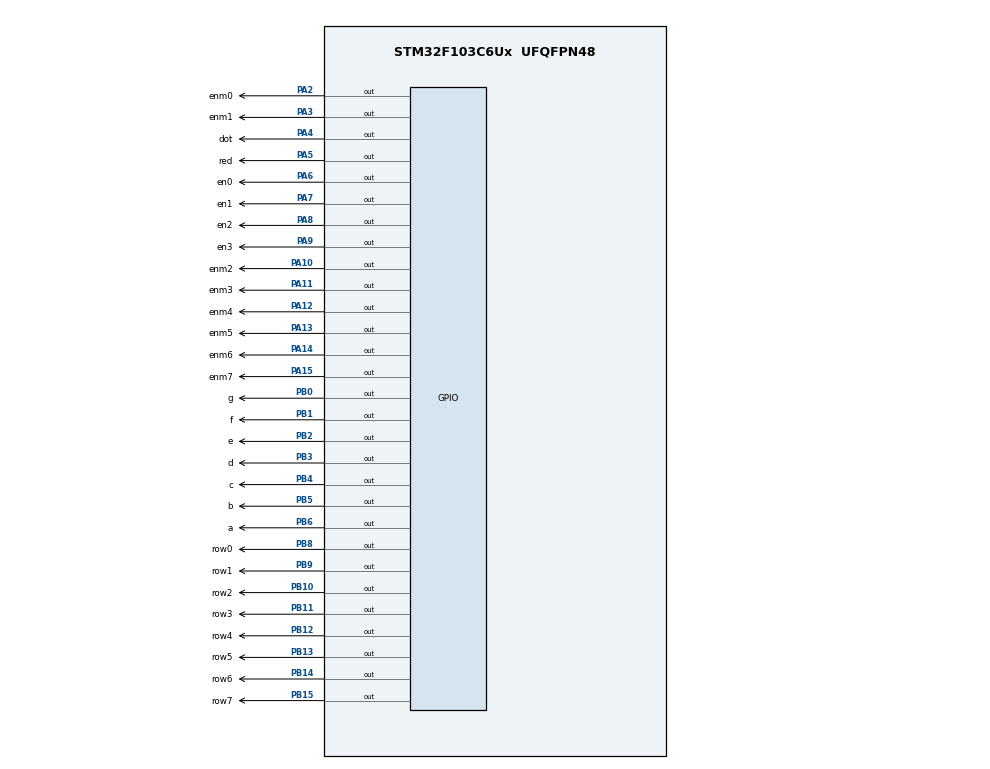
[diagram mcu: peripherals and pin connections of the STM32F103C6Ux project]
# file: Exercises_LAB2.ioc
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Mcu.Family=STM32F1
Mcu.Name=STM32F103C6Ux
Mcu.Package=UFQFPN48
NVIC.PriorityGroup=NVIC_PRIORITYGROUP_4
NVIC.TIM2_IRQn=true\:0\:0\:false\:false\:true\:true\:true
PA10.GPIO_Label=enm2
PA10.Signal=GPIO_Output
PA11.GPIO_Label=enm3
PA11.Signal=GPIO_Output
PA12.GPIO_Label=enm4
PA12.Signal=GPIO_Output
PA13.GPIO_Label=enm5
PA13.Signal=GPIO_Output
PA14.GPIO_Label=enm6
PA14.Signal=GPIO_Output
PA15.GPIO_Label=enm7
PA15.Signal=GPIO_Output
PA2.GPIO_Label=enm0
PA2.Signal=GPIO_Output
PA3.GPIO_Label=enm1
PA3.Signal=GPIO_Output
PA4.GPIO_Label=dot
PA4.Signal=GPIO_Output
PA5.GPIO_Label=red
PA5.Signal=GPIO_Output
PA6.GPIO_Label=en0
PA6.Signal=GPIO_Output
PA7.GPIO_Label=en1
PA7.Signal=GPIO_Output
PA8.GPIO_Label=en2
PA8.Signal=GPIO_Output
PA9.GPIO_Label=en3
PA9.Signal=GPIO_Output
PB0.GPIO_Label=g
PB0.Signal=GPIO_Output
PB1.GPIO_Label=f
PB1.Signal=GPIO_Output
PB10.GPIO_Label=row2
PB10.Signal=GPIO_Output
PB11.GPIO_Label=row3
PB11.Signal=GPIO_Output
PB12.GPIO_Label=row4
PB12.Signal=GPIO_Output
PB13.GPIO_Label=row5
PB13.Signal=GPIO_Output
PB14.GPIO_Label=row6
PB14.Signal=GPIO_Output
PB15.GPIO_Label=row7
PB15.Signal=GPIO_Output
PB2.GPIO_Label=e
PB2.Signal=GPIO_Output
PB3.GPIO_Label=d
PB3.Signal=GPIO_Output
PB4.GPIO_Label=c
PB4.Signal=GPIO_Output
PB5.GPIO_Label=b
PB5.Signal=GPIO_Output
PB6.GPIO_Label=a
PB6.Signal=GPIO_Output
PB8.GPIO_Label=row0
PB8.Signal=GPIO_Output
PB9.GPIO_Label=row1
PB9.Signal=GPIO_Output
ProjectManager.HeapSize=0x200
ProjectManager.StackSize=0x400
ProjectManager.TargetToolchain=STM32CubeIDE
RCC.APB1Freq_Value=8000000
RCC.APB2Freq_Value=8000000
TIM2.Period=9
TIM2.Prescaler=7999
VP_SYS_VS_ND.Mode=No_Debug
VP_TIM2_VS_ClockSourceINT.Mode=Internal
board=custom

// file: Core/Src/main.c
/* USER CODE BEGIN Header */
/**
  ******************************************************************************
  * @file           : main.c
  * @brief          : Main program body
  ******************************************************************************
  * @attention
  *
  * <h2><center>&copy; Copyright (c) 2023 STMicroelectronics.
  * All rights reserved.</center></h2>
  *
  * This software component is licensed by ST under BSD 3-Clause license,
  * the "License"; You may not use this file except in compliance with the
  * License. You may obtain a copy of the License at:
  *                        opensource.org/licenses/BSD-3-Clause
  *
  ******************************************************************************
  */
/* USER CODE END Header */
#include "main.h"

//#include "software_timer.c"
#include "software_timer.h"//ADD

TIM_HandleTypeDef htim2;

void SystemClock_Config(void);
static void MX_GPIO_Init(void);
static void MX_TIM2_Init(void);

int timer1_counter = 0;
int timer2_counter = 0;
int timer3_counter = 0;
int timer4_counter = 0;
int timer1_flag = 0;
int timer2_flag = 0;
int timer3_flag = 0;
int timer4_flag = 0;

void setTimer1(int duration)
{
	timer1_counter = duration;
	timer1_flag = 0;
}

void setTimer2(int duration)
{
	timer2_counter = duration;
	timer2_flag = 0;
}

void setTimer3(int duration)
{
	timer3_counter = duration;
	timer3_flag = 0;
}

void setTimer4(int duration)
{
	timer4_counter = duration;
	timer4_flag = 0;
}

void timerRun()
{
	if(timer1_counter > 0)
	{
		timer1_counter--;
		if(timer1_counter <= 0)
		{
			timer1_flag = 1;
		}
	}
}

void timerRun2()
{
	if(timer2_counter > 0)
	{
		timer2_counter--;
		if(timer2_counter <= 0)
		{
			timer2_flag = 1;
		}
	}
}

void timerRun3()
{
	if(timer3_counter > 0)
	{
		timer3_counter--;
		if(timer3_counter <= 0)
		{
			timer3_flag = 1;
		}
	}
}

void timerRun4()
{
	if(timer4_counter > 0)
	{
		timer4_counter--;
		if(timer4_counter <= 0)
		{
			timer4_flag = 1;
		}
	}
}
//ADD

GPIO_TypeDef* seg_port[] = {a_GPIO_Port, b_GPIO_Port, c_GPIO_Port, d_GPIO_Port, e_GPIO_Port, f_GPIO_Port, g_GPIO_Port};
int seg_pin[] = {a_Pin, b_Pin, c_Pin, d_Pin, e_Pin, f_Pin, g_Pin};
int seg_config[10] = {0x01, 0x4F, 0x12, 0x06, 0x4C, 0x24, 0x20, 0x0F, 0x00, 0x04};
// Hexadecimal to Binary: 0x01->0x00000001, 0x4F->01001111, ...

void display7SEG(int num)
{
	GPIOB->ODR = seg_config[num];
}

const int MAX_LED = 4;
int index_led = 0;
int led_buffer[4] = {1, 2, 3, 4};
void update7SEG(int index)
{
    switch (index)
    {
        case 0:
            //Display the first 7SEG with led_buffer[0]
    		HAL_GPIO_WritePin(en0_GPIO_Port, en0_Pin, RESET);
    		HAL_GPIO_WritePin(GPIOA, en1_Pin | en2_Pin | en3_Pin, SET);
    		display7SEG(led_buffer[index]);
            break;
        case 1:
            //Display the second 7SEG with led_buffer[1]
  		    HAL_GPIO_WritePin(en1_GPIO_Port, en1_Pin, RESET);
    		HAL_GPIO_WritePin(GPIOA, en0_Pin | en2_Pin | en3_Pin, SET);
    		display7SEG(led_buffer[index]);
            break;
        case 2:
            //Display the third 7SEG with led_buffer[2]
  		    HAL_GPIO_WritePin(en2_GPIO_Port, en2_Pin, RESET);
    		HAL_GPIO_WritePin(GPIOA, en0_Pin | en1_Pin | en3_Pin, SET);
    		display7SEG(led_buffer[index]);
            break;
        case 3:
            //Display the forth 7SEG with led_buffer[3]
  		    HAL_GPIO_WritePin(en3_GPIO_Port, en3_Pin, RESET);
    		HAL_GPIO_WritePin(GPIOA, en0_Pin | en1_Pin | en2_Pin, SET);
    		display7SEG(led_buffer[index]);
            break;
        default:
            break;
    }
}

void updateClockBuffer(int hour, int minute)
{
    led_buffer[0] = hour / 10;
    led_buffer[1] = hour % 10;
    led_buffer[2] = minute / 10;
    led_buffer[3] = minute % 10;
}

const int MAX_LED_MATRIX = 8;
int index_led_matrix = 0;
int state = 0;
uint8_t matrix_buffer[8] = {0x01, 0x02, 0x03, 0x04, 0x05, 0x06, 0x07, 0x08};

uint8_t row_buffer[8] = {0x01, 0x02, 0x04, 0x08, 0x10, 0x20, 0x40, 0x80};

uint8_t col_buffer[8][8] =
{
{0x18, 0x3C, 0x66, 0x66, 0x7E, 0x7E, 0x66, 0x66},
{0x30, 0x78, 0xCC, 0xCC, 0xFC, 0xFC, 0xCC, 0xCC},
{0x60, 0xF0, 0x99, 0x99, 0xF9, 0xF9, 0x99, 0x99},
{0xC0, 0xE1, 0x33, 0x33, 0xF3, 0xF3, 0x33, 0x33},
{0x81, 0xC3, 0x66, 0x66, 0xE7, 0xE7, 0x66, 0x66},
{0x03, 0x87, 0xCC, 0xCC, 0xCF, 0xCF, 0xCC, 0xCC},
{0x06, 0x0F, 0x99, 0x99, 0x9F, 0x9F, 0x99, 0x99},
{0x0C, 0x1E, 0x33, 0x33, 0x3F, 0x3F, 0x33, 0x33}
};

void displayCol (int state, int index)
{
	  HAL_GPIO_WritePin(row0_GPIO_Port,row0_Pin, ((col_buffer[state][index]>>0)&0x01));
	  HAL_GPIO_WritePin(row1_GPIO_Port,row1_Pin, ((col_buffer[state][index]>>1)&0x01));
	  HAL_GPIO_WritePin(row2_GPIO_Port,row2_Pin, ((col_buffer[state][index]>>2)&0x01));
	  HAL_GPIO_WritePin(row3_GPIO_Port,row3_Pin, ((col_buffer[state][index]>>3)&0x01));
	  HAL_GPIO_WritePin(row4_GPIO_Port,row4_Pin, ((col_buffer[state][index]>>4)&0x01));
	  HAL_GPIO_WritePin(row5_GPIO_Port,row5_Pin, ((col_buffer[state][index]>>5)&0x01));
	  HAL_GPIO_WritePin(row6_GPIO_Port,row6_Pin, ((col_buffer[state][index]>>6)&0x01));
	  HAL_GPIO_WritePin(row7_GPIO_Port,row7_Pin, ((col_buffer[state][index]>>7)&0x01));
}

void displayRow (int index)
{
	  HAL_GPIO_WritePin(enm0_GPIO_Port, enm0_Pin, ((row_buffer[index]>>0)&0x01));
	  HAL_GPIO_WritePin(enm1_GPIO_Port, enm1_Pin, ((row_buffer[index]>>1)&0x01));
	  HAL_GPIO_WritePin(enm2_GPIO_Port, enm2_Pin, ((row_buffer[index]>>2)&0x01));
	  HAL_GPIO_WritePin(enm3_GPIO_Port, enm3_Pin, ((row_buffer[index]>>3)&0x01));
	  HAL_GPIO_WritePin(enm4_GPIO_Port, enm4_Pin, ((row_buffer[index]>>4)&0x01));
	  HAL_GPIO_WritePin(enm5_GPIO_Port, enm5_Pin, ((row_buffer[index]>>5)&0x01));
	  HAL_GPIO_WritePin(enm6_GPIO_Port, enm6_Pin, ((row_buffer[index]>>6)&0x01));
	  HAL_GPIO_WritePin(enm7_GPIO_Port, enm7_Pin, ((row_buffer[index]>>7)&0x01));
}

void updateLEDMatrix(int sate, int index)
{
    switch (index)
    {
        case 0:
        	displayRow(index);
        	displayCol(state, index);
            break;
        case 1:
        	displayRow(index);
        	displayCol(state, index);
            break;
        case 2:
        	displayRow(index);
        	displayCol(state, index);
            break;
        case 3:
        	displayRow(index);
        	displayCol(state, index);
            break;
        case 4:
        	displayRow(index);
        	displayCol(state, index);
            break;
        case 5:
        	displayRow(index);
        	displayCol(state, index);
            break;
        case 6:
        	displayRow(index);
        	displayCol(state, index);
            break;
        case 7:
        	displayRow(index);
        	displayCol(state, index);
            break;
        default:
            break;
    }
}

int main(void)
{

  /* MCU Configuration--------------------------------------------------------*/

  /* Reset of all peripherals, Initializes the Flash interface and the Systick. */
  HAL_Init();

  /* Configure the system clock */
  SystemClock_Config();

  /* Initialize all configured peripherals */
  MX_GPIO_Init();
  MX_TIM2_Init();
  /* USER CODE BEGIN 2 */
  HAL_TIM_Base_Start_IT(&htim2);
  /* USER CODE END 2 */

  /* Infinite loop */
  /* USER CODE BEGIN WHILE */
  int hour = 15, minute = 8, second = 50;
  setTimer1(25);
  setTimer2(100);
  setTimer3(3);
  setTimer4(100);
  while (1)
  {
    /* USER CODE END WHILE */

	  if(timer1_flag == 1)
	  {
		  setTimer1(25);
		  update7SEG(index_led++);
		  if(index_led >= 4)	index_led = 0;
	  }

	  if(timer2_flag == 1)
	  {
		    setTimer2(100);
		    second++;
		    if (second >= 60)
		    {
		        second = 0;
		        minute++;
		    }
		    if(minute >= 60)
		    {
		        minute = 0;
		        hour++;
		    }
		    if(hour >=24)
		    {
		        hour = 0;
		    }
		    updateClockBuffer(hour, minute);
	  }

	  if(timer3_flag == 1)
	  {
		  setTimer3(3);
		  updateLEDMatrix(state, index_led_matrix++);
	  }
	  if(timer4_flag == 1)
	  {
		  setTimer4(100);
		  HAL_GPIO_TogglePin(dot_GPIO_Port, dot_Pin);
	  }
	  if(index_led_matrix >= MAX_LED_MATRIX)
	  {
		  index_led_matrix = 0;
		  state++;
		  if(state >= MAX_LED_MATRIX)	state = 0;
	  }
  }
}

void SystemClock_Config(void)
{
  RCC_OscInitTypeDef RCC_OscInitStruct = {0};
  RCC_ClkInitTypeDef RCC_ClkInitStruct = {0};

  /** Initializes the RCC Oscillators according to the specified parameters
  * in the RCC_OscInitTypeDef structure.
  */
  RCC_OscInitStruct.OscillatorType = RCC_OSCILLATORTYPE_HSI;
  RCC_OscInitStruct.HSIState = RCC_HSI_ON;
  RCC_OscInitStruct.HSICalibrationValue = RCC_HSICALIBRATION_DEFAULT;
  RCC_OscInitStruct.PLL.PLLState = RCC_PLL_NONE;
  if (HAL_RCC_OscConfig(&RCC_OscInitStruct) != HAL_OK)
  {
    Error_Handler();
  }
  /** Initializes the CPU, AHB and APB buses clocks
  */
  RCC_ClkInitStruct.ClockType = RCC_CLOCKTYPE_HCLK|RCC_CLOCKTYPE_SYSCLK
                              |RCC_CLOCKTYPE_PCLK1|RCC_CLOCKTYPE_PCLK2;
  RCC_ClkInitStruct.SYSCLKSource = RCC_SYSCLKSOURCE_HSI;
  RCC_ClkInitStruct.AHBCLKDivider = RCC_SYSCLK_DIV1;
  RCC_ClkInitStruct.APB1CLKDivider = RCC_HCLK_DIV1;
  RCC_ClkInitStruct.APB2CLKDivider = RCC_HCLK_DIV1;

  if (HAL_RCC_ClockConfig(&RCC_ClkInitStruct, FLASH_LATENCY_0) != HAL_OK)
  {
    Error_Handler();
  }
}

static void MX_TIM2_Init(void)
{

  TIM_ClockConfigTypeDef sClockSourceConfig = {0};
  TIM_MasterConfigTypeDef sMasterConfig = {0};

  htim2.Instance = TIM2;
  htim2.Init.Prescaler = 7999;
  htim2.Init.CounterMode = TIM_COUNTERMODE_UP;
  htim2.Init.Period = 9;
  htim2.Init.ClockDivision = TIM_CLOCKDIVISION_DIV1;
  htim2.Init.AutoReloadPreload = TIM_AUTORELOAD_PRELOAD_DISABLE;
  if (HAL_TIM_Base_Init(&htim2) != HAL_OK)
  {
    Error_Handler();
  }
  sClockSourceConfig.ClockSource = TIM_CLOCKSOURCE_INTERNAL;
  if (HAL_TIM_ConfigClockSource(&htim2, &sClockSourceConfig) != HAL_OK)
  {
    Error_Handler();
  }
  sMasterConfig.MasterOutputTrigger = TIM_TRGO_RESET;
  sMasterConfig.MasterSlaveMode = TIM_MASTERSLAVEMODE_DISABLE;
  if (HAL_TIMEx_MasterConfigSynchronization(&htim2, &sMasterConfig) != HAL_OK)
  {
    Error_Handler();
  }

}

static void MX_GPIO_Init(void)
{
  GPIO_InitTypeDef GPIO_InitStruct = {0};

  /* GPIO Ports Clock Enable */
  __HAL_RCC_GPIOA_CLK_ENABLE();
  __HAL_RCC_GPIOB_CLK_ENABLE();

  /*Configure GPIO pin Output Level */
  HAL_GPIO_WritePin(GPIOA, enm0_Pin|enm1_Pin|dot_Pin|red_Pin
                          |en0_Pin|en1_Pin|en2_Pin|en3_Pin
                          |enm2_Pin|enm3_Pin|enm4_Pin|enm5_Pin
                          |enm6_Pin|enm7_Pin, GPIO_PIN_RESET);

  /*Configure GPIO pin Output Level */
  HAL_GPIO_WritePin(GPIOB, g_Pin|f_Pin|e_Pin|row2_Pin
                          |row3_Pin|row4_Pin|row5_Pin|row6_Pin
                          |row7_Pin|d_Pin|c_Pin|b_Pin
                          |a_Pin|row0_Pin|row1_Pin, GPIO_PIN_RESET);

  /*Configure GPIO pins : enm0_Pin enm1_Pin dot_Pin red_Pin
                           en0_Pin en1_Pin en2_Pin en3_Pin
                           enm2_Pin enm3_Pin enm4_Pin enm5_Pin
                           enm6_Pin enm7_Pin */
  GPIO_InitStruct.Pin = enm0_Pin|enm1_Pin|dot_Pin|red_Pin
                          |en0_Pin|en1_Pin|en2_Pin|en3_Pin
                          |enm2_Pin|enm3_Pin|enm4_Pin|enm5_Pin
                          |enm6_Pin|enm7_Pin;
  GPIO_InitStruct.Mode = GPIO_MODE_OUTPUT_PP;
  GPIO_InitStruct.Pull = GPIO_NOPULL;
  GPIO_InitStruct.Speed = GPIO_SPEED_FREQ_LOW;
  HAL_GPIO_Init(GPIOA, &GPIO_InitStruct);

  /*Configure GPIO pins : g_Pin f_Pin e_Pin row2_Pin
                           row3_Pin row4_Pin row5_Pin row6_Pin
                           row7_Pin d_Pin c_Pin b_Pin
                           a_Pin row0_Pin row1_Pin */
  GPIO_InitStruct.Pin = g_Pin|f_Pin|e_Pin|row2_Pin
                          |row3_Pin|row4_Pin|row5_Pin|row6_Pin
                          |row7_Pin|d_Pin|c_Pin|b_Pin
                          |a_Pin|row0_Pin|row1_Pin;
  GPIO_InitStruct.Mode = GPIO_MODE_OUTPUT_PP;
  GPIO_InitStruct.Pull = GPIO_NOPULL;
  GPIO_InitStruct.Speed = GPIO_SPEED_FREQ_LOW;
  HAL_GPIO_Init(GPIOB, &GPIO_InitStruct);

}

/* USER CODE BEGIN 4 */
void HAL_TIM_PeriodElapsedCallback (TIM_HandleTypeDef *htim)
{
	timerRun();
	timerRun2();
	timerRun3();
	timerRun4();
}
/* USER CODE END 4 */

void Error_Handler(void)
{
  __disable_irq();
  while (1)
  {
  }
}

/************************ (C) COPYRIGHT STMicroelectronics *****END OF FILE****/
